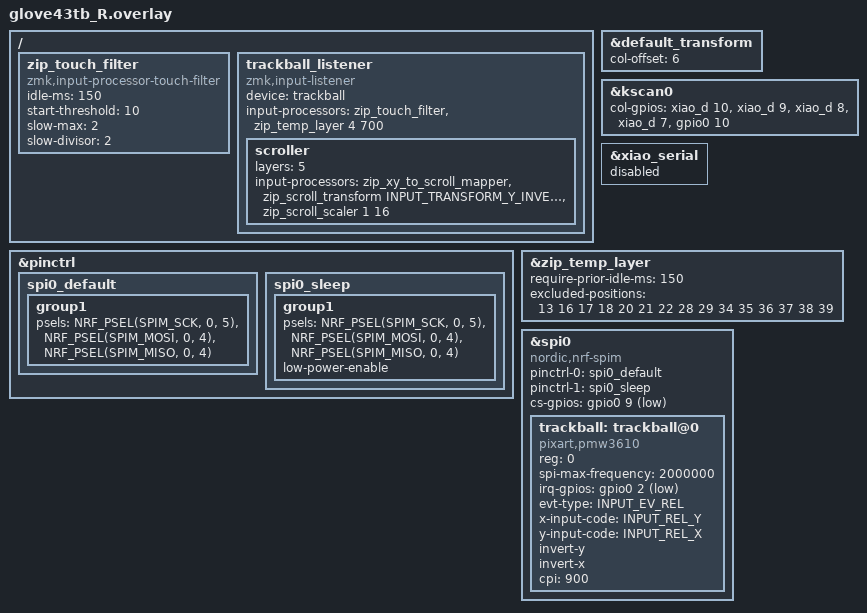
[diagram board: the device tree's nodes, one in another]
#include "glove43tb.dtsi"
#include <zephyr/dt-bindings/input/input-event-codes.h>
#include <dt-bindings/zmk/input_transform.h>
#include <input/processors.dtsi>

&default_transform {
    col-offset = <6>;
};

&kscan0 {
        col-gpios
            = <&xiao_d 10 GPIO_ACTIVE_HIGH>
            , <&xiao_d 9 GPIO_ACTIVE_HIGH>
            , <&xiao_d 8 GPIO_ACTIVE_HIGH>
            , <&xiao_d 7 GPIO_ACTIVE_HIGH>
            , <&gpio0 10 GPIO_ACTIVE_HIGH>
            ;
};

/ {
    // トラックボールに軽く触れたときのブレ対策 (src/pointing/input_processor_touch_filter.c)
    zip_touch_filter: zip_touch_filter {
        compatible = "zmk,input-processor-touch-filter";
        #input-processor-cells = <0>;
        idle-ms = <150>;          // この時間(ms)動きがなければ「停止中」とみなす
        start-threshold = <10>;   // 停止中からの動き出しは、この量(カウント)動くまで無視する(大きいほどブレに強い)
        slow-max = <2>;           // 1回の移動量がこれ以下のとても遅い動きは…
        slow-divisor = <2>;       // …この値で割って減速する(1で無効)
    };

    trackball_listener {
        status = "okay";
        compatible = "zmk,input-listener";
        device = <&trackball>;
        input-processors = <&zip_touch_filter &zip_temp_layer 4 700>;  // ブレ対策 → オートマウスレイヤー（AML）: トラックボール動作時に自動的にレイヤー4を有効化（700ms）

        scroller {
            layers = <5>;                                      // スクロールレイヤー
            input-processors = <
                &zip_xy_to_scroll_mapper                       // XY移動でスクロール
//                &zip_scroll_transform INPUT_TRANSFORM_X_INVERT // スクロールのX軸を反転
                &zip_scroll_transform INPUT_TRANSFORM_Y_INVERT // スクロールのY軸を反転
                &zip_scroll_scaler 1 16                        // スクロール感度調整
            >;
        };
    };
};

&pinctrl {
    spi0_default: spi0_default {
        group1 {
            psels = <NRF_PSEL(SPIM_SCK, 0, 5)>,
                <NRF_PSEL(SPIM_MOSI, 0, 4)>,
                <NRF_PSEL(SPIM_MISO, 0, 4)>;
        };
    };

    spi0_sleep: spi0_sleep {
        group1 {
            psels = <NRF_PSEL(SPIM_SCK, 0, 5)>,
                <NRF_PSEL(SPIM_MOSI, 0, 4)>,
                <NRF_PSEL(SPIM_MISO, 0, 4)>;
            low-power-enable;
        };
    };
};

&xiao_serial { status = "disabled"; };

// オートマウス: 直前150ms以内にタイピングしていたら発動しない。下記以外のキーを押すと即解除
// (マウスボタン, Ctrl/C/X/V, 修飾キーの位置)
&zip_temp_layer {
    require-prior-idle-ms = <150>;
    excluded-positions = <13 16 17 18 20 21 22 28 29 34 35 36 37 38 39>;
};

&spi0 {
    status = "okay";
    compatible = "nordic,nrf-spim";
    pinctrl-0 = <&spi0_default>;
    pinctrl-1 = <&spi0_sleep>;
    pinctrl-names = "default", "sleep";
    cs-gpios = <&gpio0 9 GPIO_ACTIVE_LOW>;

    trackball: trackball@0 {
        status = "okay";
        compatible = "pixart,pmw3610";
        reg = <0>;
        spi-max-frequency = <2000000>;
        irq-gpios = <&gpio0 2 (GPIO_ACTIVE_LOW | GPIO_PULL_UP)>;
        evt-type = <INPUT_EV_REL>;
        x-input-code = <INPUT_REL_Y>;
        y-input-code = <INPUT_REL_X>;
        invert-y;     // マウス操作のY軸を反転
        invert-x;     // マウス操作のX軸を反転
        cpi = <900>;  // マウス感度
    };
};
